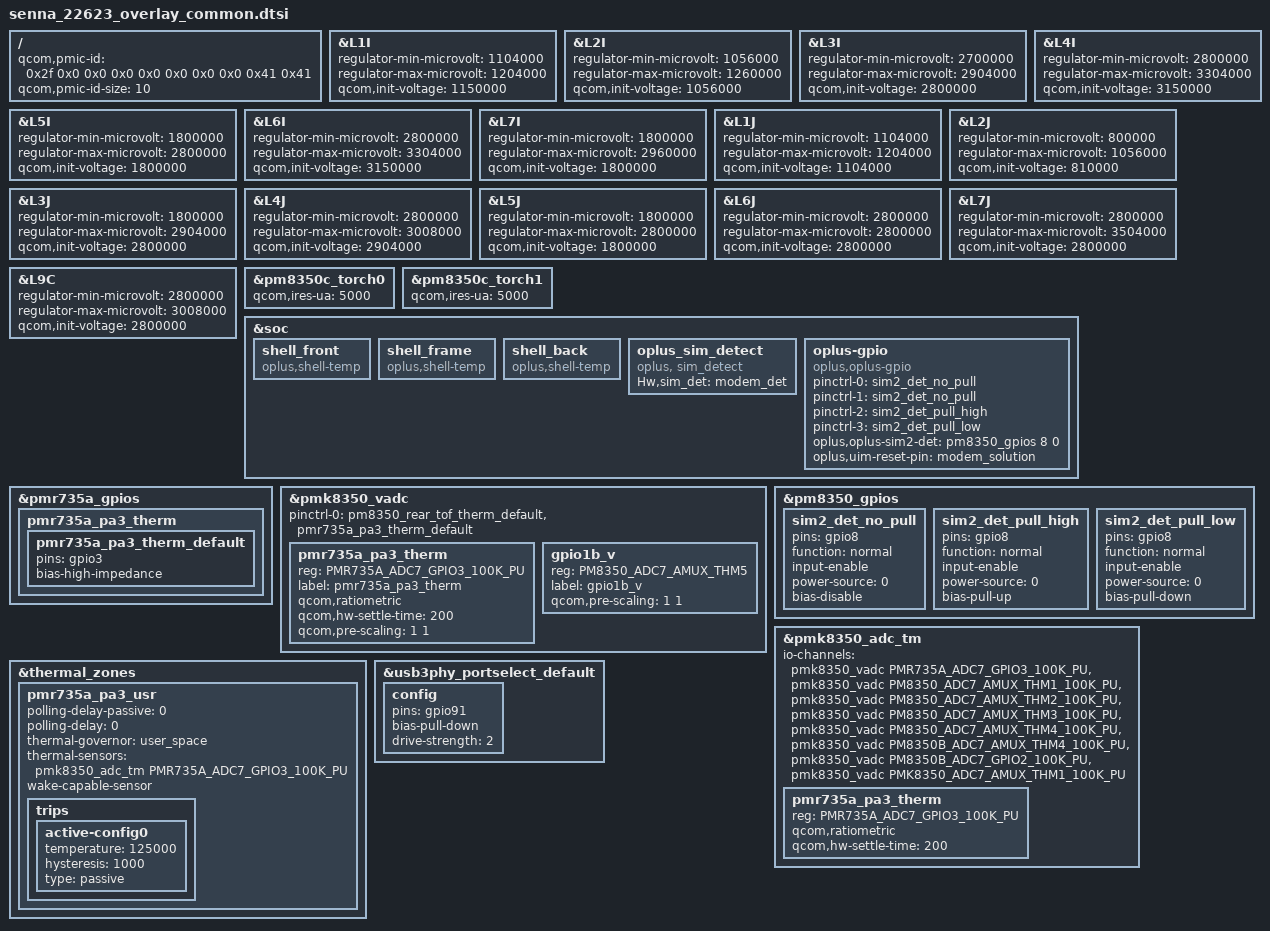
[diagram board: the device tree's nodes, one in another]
#include "tp/senna_22623_extra_config.dtsi"


/* Cape configurations for PM8010I and PM8010J connected via SPMI */

#include <dt-bindings/regulator/qcom,rpmh-regulator-levels.h>

/ {
	qcom,pmic-id = <0x2f 0x0 0x0 0x0 0x0 0x0 0x0 0x0 0x41 0x41>;
	qcom,pmic-id-size = <10>;
};
&L1I {
  regulator-min-microvolt = <1104000>;
  regulator-max-microvolt = <1204000>;
  qcom,init-voltage = <1150000>;
};

&L2I {
  regulator-min-microvolt = <1056000>;
  regulator-max-microvolt = <1260000>;
  qcom,init-voltage = <1056000>;
};

&L3I {
  regulator-min-microvolt = <2700000>;
  regulator-max-microvolt = <2904000>;
  qcom,init-voltage = <2800000>;
};

&L4I {
  regulator-min-microvolt = <2800000>;
  regulator-max-microvolt = <3304000>;
  qcom,init-voltage = <3150000>;
};

&L5I {
  regulator-min-microvolt = <1800000>;
  regulator-max-microvolt = <2800000>;
  qcom,init-voltage = <1800000>;
};

&L6I {
  regulator-min-microvolt = <2800000>;
  regulator-max-microvolt = <3304000>;
  qcom,init-voltage = <3150000>;
};

&L7I {
  regulator-min-microvolt = <1800000>;
  regulator-max-microvolt = <2960000>;
  qcom,init-voltage = <1800000>;
};

&L1J {
  regulator-min-microvolt = <1104000>;
  regulator-max-microvolt = <1204000>;
  qcom,init-voltage = <1104000>;
};

&L2J {
  regulator-min-microvolt = <800000>;
  regulator-max-microvolt = <1056000>;
  qcom,init-voltage = <810000>;
};

&L3J {
  regulator-min-microvolt = <1800000>;
  regulator-max-microvolt = <2904000>;
  qcom,init-voltage = <2800000>;
};

&L4J {
  regulator-min-microvolt = <2800000>;
  regulator-max-microvolt = <3008000>;
  qcom,init-voltage = <2904000>;
};

&L5J {
  regulator-min-microvolt = <1800000>;
  regulator-max-microvolt = <2800000>;
  qcom,init-voltage = <1800000>;
};

&L6J {
  regulator-min-microvolt = <2800000>;
  regulator-max-microvolt = <2800000>;
  qcom,init-voltage = <2800000>;
};

&L7J {
  regulator-min-microvolt = <2800000>;
  regulator-max-microvolt = <3504000>;
  qcom,init-voltage = <2800000>;
};
&L9C {
  regulator-min-microvolt = <2800000>;
  regulator-max-microvolt = <3008000>;
  qcom,init-voltage = <2800000>;
};

&pm8350c_torch0 {
	qcom,ires-ua = <5000>;
};

&pm8350c_torch1 {
	qcom,ires-ua = <5000>;
};


&soc {
	//#ifdef OPLUS_FEATURE_THERMAL_HORAE
	shell_front {
			compatible = "oplus,shell-temp";
	};

	shell_frame {
			compatible = "oplus,shell-temp";
	};

	shell_back {
			compatible = "oplus,shell-temp";
	};
	//#endif
};

&pmr735a_gpios {
	pmr735a_pa3_therm {
         pmr735a_pa3_therm_default: pmr735a_pa3_therm_default {
               pins = "gpio3";
               bias-high-impedance;
         };
      };
};

&pmk8350_vadc {
	pinctrl-names = "default";
	pinctrl-0 = <&pm8350_rear_tof_therm_default &pmr735a_pa3_therm_default>;

	/delete-node/ pm8350_rear_tof_therm;

	pmr735a_pa3_therm {
		reg = <PMR735A_ADC7_GPIO3_100K_PU>;
		label = "pmr735a_pa3_therm";
		qcom,ratiometric;
		qcom,hw-settle-time = <200>;
		qcom,pre-scaling = <1 1>;
	};

    gpio1b_v {
        reg = <PM8350_ADC7_AMUX_THM5>;
        label = "gpio1b_v";
        qcom,pre-scaling = <1 1>;
    };
};

&pmr735a_gpios {
	pmr735a_pa3_therm {
         pmr735a_pa3_therm_default: pmr735a_pa3_therm_default {
               pins = "gpio3";
               bias-high-impedance;
         };
      };
};

&pm8350_gpios {
	//#ifdef OPLUS_FEATRUE_DUAL_SIM_DETECT
	sim2_det_no_pull: sim2_det_no_pull {
			pins = "gpio8";
			function = "normal";
			input-enable;
			power-source = <0>;
			bias-disable;
	};

	sim2_det_pull_high: sim2_det_pull_high {
			pins = "gpio8";
			function = "normal";
			input-enable;
			power-source = <0>;
			bias-pull-up;
	};

	sim2_det_pull_low: sim2_det_pull_low {
			pins = "gpio8";
			function = "normal";
			input-enable;
			power-source = <0>;
			bias-pull-down;
	};
	//#endif OPLUS_FEATRUE_DUAL_SIM_DETECT
};

&pmk8350_adc_tm {
	io-channels = <&pmk8350_vadc PMR735A_ADC7_GPIO3_100K_PU>,
			<&pmk8350_vadc PM8350_ADC7_AMUX_THM1_100K_PU>,
			<&pmk8350_vadc PM8350_ADC7_AMUX_THM2_100K_PU>,
			<&pmk8350_vadc PM8350_ADC7_AMUX_THM3_100K_PU>,
			<&pmk8350_vadc PM8350_ADC7_AMUX_THM4_100K_PU>,
//			<&pmk8350_vadc PM8350_ADC7_AMUX_THM5_100K_PU>,
			<&pmk8350_vadc PM8350B_ADC7_AMUX_THM4_100K_PU>,
			<&pmk8350_vadc PM8350B_ADC7_GPIO2_100K_PU>,
			<&pmk8350_vadc PMK8350_ADC7_AMUX_THM1_100K_PU>;

	/delete-node/ pm8350_rear_tof_therm;

	pmr735a_pa3_therm {
		reg = <PMR735A_ADC7_GPIO3_100K_PU>;
		qcom,ratiometric;
		qcom,hw-settle-time = <200>;
	};
};

&thermal_zones {

	/delete-node/ pm8350_rear_tof_therm;

	pmr735a_pa3_usr {
		polling-delay-passive = <0>;
		polling-delay = <0>;
		thermal-governor = "user_space";
		thermal-sensors = <&pmk8350_adc_tm PMR735A_ADC7_GPIO3_100K_PU>;
		wake-capable-sensor;
		trips {
			active-config0 {
				temperature = <125000>;
				hysteresis = <1000>;
				type = "passive";
			};
		};
	};
};

//Add to change cc-out gpio pull down
&usb3phy_portselect_default {
	config {
		pins = "gpio91";
		bias-pull-down;
		drive-strength = <2>;
	};
};

&soc {
	//#ifdef OPLUS_FEATRUE_SIM_HOLDER_DETECT
	oplus_sim_detect {
		compatible = "oplus, sim_detect";
		Hw,sim_det = "modem_det";
	};
	//#endif /* OPLUS_FEATRUE_SIM_HOLDER_DETECT */

	//#ifdef OPLUS_FEATRUE_DUAL_SIM_DETECT
	oplus-gpio {
		compatible = "oplus,oplus-gpio";
		pinctrl-names = "default", "sim2_det_no_pull", "sim2_det_pull_high", "sim2_det_pull_low";
		pinctrl-0 = <&sim2_det_no_pull>;
		pinctrl-1 = <&sim2_det_no_pull>;
		pinctrl-2 = <&sim2_det_pull_high>;
		pinctrl-3 = <&sim2_det_pull_low>;
		oplus,oplus-sim2-det = <&pm8350_gpios 8 0>;
		oplus,uim-reset-pin = "modem_solution";
	};
	//#endif /* OPLUS_FEATRUE_DUAL_SIM_DETECT */
};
